VERSION ""

NS_ :

BS_:

BU_: VCU LED
VAL_TABLE_ Mode 2 "CHARGE" 1 "ALL ON" 0 "ALL OFF" ;

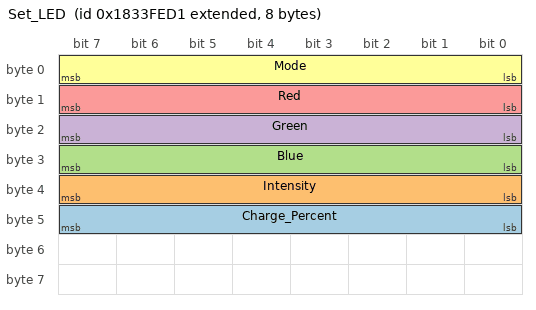
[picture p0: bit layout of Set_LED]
BO_ 2553544401 Set_LED: 8 Vector__XXX
 SG_ Charge_Percent : 40|8@1+ (1,0) [0|100] "%" Vector__XXX
 SG_ Intensity : 32|8@1+ (1,0) [0|255] "" Vector__XXX
 SG_ Blue : 24|8@1+ (1,0) [0|255] "" Vector__XXX
 SG_ Green : 16|8@1+ (1,0) [0|255] "" Vector__XXX
 SG_ Red : 8|8@1+ (1,0) [0|255] "" Vector__XXX
 SG_ Mode : 0|8@1+ (1,0) [0|255] "" Vector__XXX

BA_DEF_ BU_  "NmStationAddress" HEX 0 0;
BA_DEF_ BO_  "GenMsgSendType" ENUM  "Cyclic","not_used","not_used","not_used","not_used","Cyclic","not_used","IfActive";
BA_DEF_DEF_  "NmStationAddress" 0;
BA_DEF_DEF_  "GenMsgSendType" "not_used";
BA_ "NmStationAddress" BU_ VCU 209;
BA_ "NmStationAddress" BU_ LED 254;
BA_ "GenMsgSendType" BO_ 2553544401 7;
VAL_ 2553544401 Mode 2 "CHARGE" 1 "ALL ON" 0 "ALL OFF" ;
